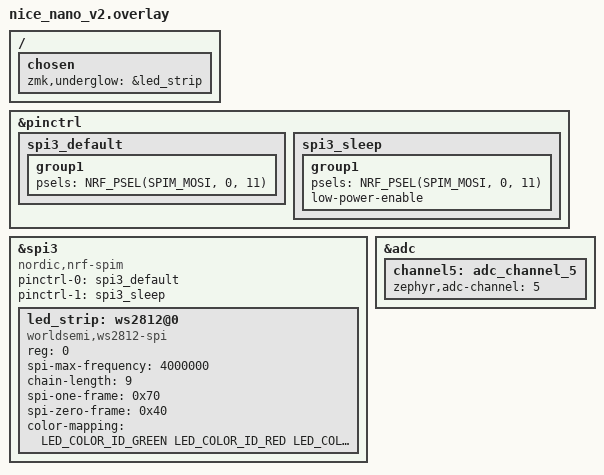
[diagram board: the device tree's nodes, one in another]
#include <dt-bindings/led/led.h>

&pinctrl {
    spi3_default: spi3_default {
        group1 {
            psels = <NRF_PSEL(SPIM_MOSI, 0, 11)>;
        };
    };

    spi3_sleep: spi3_sleep {
        group1 {
            psels = <NRF_PSEL(SPIM_MOSI, 0, 11)>;
            low-power-enable;
        };
    };
};

&spi3 {
    compatible = "nordic,nrf-spim";
    status = "okay";

    pinctrl-0 = <&spi3_default>;
    pinctrl-1 = <&spi3_sleep>;
    pinctrl-names = "default", "sleep";

    led_strip: ws2812@0 {
        compatible = "worldsemi,ws2812-spi";

        /* SPI */
        reg = <0>; /* ignored, but necessary for SPI bindings */
        spi-max-frequency = <4000000>;

        /* WS2812 */
        chain-length = <9>;
        spi-one-frame = <0x70>;
        spi-zero-frame = <0x40>;

        color-mapping = <LED_COLOR_ID_GREEN LED_COLOR_ID_RED LED_COLOR_ID_BLUE>;
    };
};

&adc {
    status = "okay";

    channel5: adc_channel_5 {
        zephyr,adc-channel = <5>;         /* SAADC AIN5 */
        // zephyr,gain = "1/6";              /* 0.6V × 6 = 3.6V full-scale */
        // zephyr,reference = "internal";    /* 0.6V reference */
        // zephyr,acquisition-time = <40>;   /* standard */
    };

};

/ {
    chosen {
        zmk,underglow = &led_strip;
    };
};
